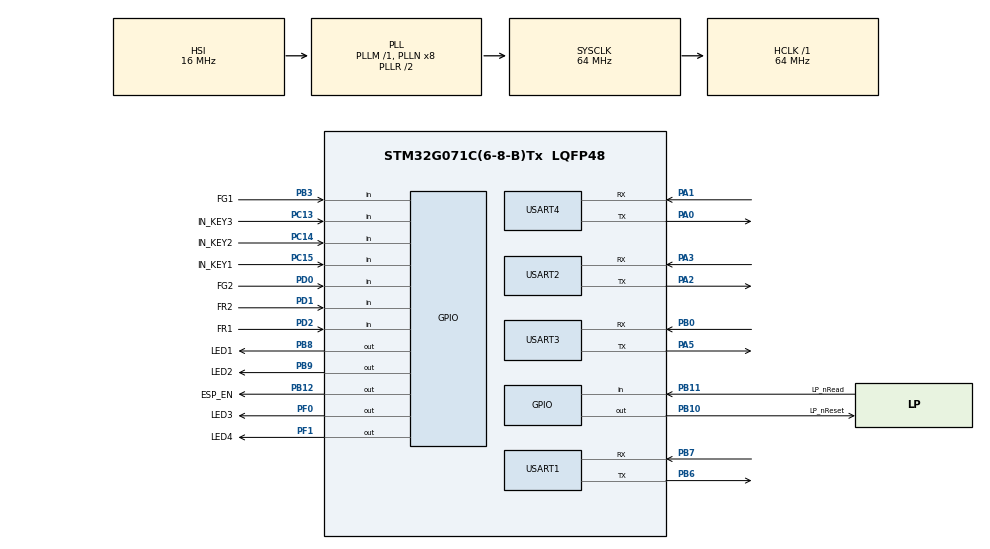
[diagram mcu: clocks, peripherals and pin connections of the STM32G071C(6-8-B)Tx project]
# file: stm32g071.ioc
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Dma.Request0=USART1_RX
Dma.Request1=USART1_TX
Dma.Request2=USART2_RX
Dma.Request3=USART2_TX
Dma.USART1_RX.0.Direction=DMA_PERIPH_TO_MEMORY
Dma.USART1_RX.0.EventEnable=DISABLE
Dma.USART1_RX.0.Instance=DMA1_Channel1
Dma.USART1_RX.0.MemDataAlignment=DMA_MDATAALIGN_BYTE
Dma.USART1_RX.0.MemInc=DMA_MINC_ENABLE
Dma.USART1_RX.0.Mode=DMA_NORMAL
Dma.USART1_RX.0.PeriphDataAlignment=DMA_PDATAALIGN_BYTE
Dma.USART1_RX.0.PeriphInc=DMA_PINC_DISABLE
Dma.USART1_RX.0.Polarity=HAL_DMAMUX_REQ_GEN_RISING
Dma.USART1_RX.0.Priority=DMA_PRIORITY_LOW
Dma.USART1_RX.0.RequestNumber=1
Dma.USART1_RX.0.SignalID=NONE
Dma.USART1_RX.0.SyncEnable=DISABLE
Dma.USART1_RX.0.SyncPolarity=HAL_DMAMUX_SYNC_NO_EVENT
Dma.USART1_RX.0.SyncRequestNumber=1
Dma.USART1_RX.0.SyncSignalID=NONE
Dma.USART1_TX.1.Direction=DMA_MEMORY_TO_PERIPH
Dma.USART1_TX.1.EventEnable=DISABLE
Dma.USART1_TX.1.Instance=DMA1_Channel2
Dma.USART1_TX.1.MemDataAlignment=DMA_MDATAALIGN_BYTE
Dma.USART1_TX.1.MemInc=DMA_MINC_ENABLE
Dma.USART1_TX.1.Mode=DMA_NORMAL
Dma.USART1_TX.1.PeriphDataAlignment=DMA_PDATAALIGN_BYTE
Dma.USART1_TX.1.PeriphInc=DMA_PINC_DISABLE
Dma.USART1_TX.1.Polarity=HAL_DMAMUX_REQ_GEN_RISING
Dma.USART1_TX.1.Priority=DMA_PRIORITY_LOW
Dma.USART1_TX.1.RequestNumber=1
Dma.USART1_TX.1.SignalID=NONE
Dma.USART1_TX.1.SyncEnable=DISABLE
Dma.USART1_TX.1.SyncPolarity=HAL_DMAMUX_SYNC_NO_EVENT
Dma.USART1_TX.1.SyncRequestNumber=1
Dma.USART1_TX.1.SyncSignalID=NONE
Dma.USART2_RX.2.Direction=DMA_PERIPH_TO_MEMORY
Dma.USART2_RX.2.EventEnable=DISABLE
Dma.USART2_RX.2.Instance=DMA1_Channel3
Dma.USART2_RX.2.MemDataAlignment=DMA_MDATAALIGN_BYTE
Dma.USART2_RX.2.MemInc=DMA_MINC_ENABLE
Dma.USART2_RX.2.Mode=DMA_NORMAL
Dma.USART2_RX.2.PeriphDataAlignment=DMA_PDATAALIGN_BYTE
Dma.USART2_RX.2.PeriphInc=DMA_PINC_DISABLE
Dma.USART2_RX.2.Polarity=HAL_DMAMUX_REQ_GEN_RISING
Dma.USART2_RX.2.Priority=DMA_PRIORITY_LOW
Dma.USART2_RX.2.RequestNumber=1
Dma.USART2_RX.2.SignalID=NONE
Dma.USART2_RX.2.SyncEnable=DISABLE
Dma.USART2_RX.2.SyncPolarity=HAL_DMAMUX_SYNC_NO_EVENT
Dma.USART2_RX.2.SyncRequestNumber=1
Dma.USART2_RX.2.SyncSignalID=NONE
Dma.USART2_TX.3.Direction=DMA_MEMORY_TO_PERIPH
Dma.USART2_TX.3.EventEnable=DISABLE
Dma.USART2_TX.3.Instance=DMA1_Channel4
Dma.USART2_TX.3.MemDataAlignment=DMA_MDATAALIGN_BYTE
Dma.USART2_TX.3.MemInc=DMA_MINC_ENABLE
Dma.USART2_TX.3.Mode=DMA_NORMAL
Dma.USART2_TX.3.PeriphDataAlignment=DMA_PDATAALIGN_BYTE
Dma.USART2_TX.3.PeriphInc=DMA_PINC_DISABLE
Dma.USART2_TX.3.Polarity=HAL_DMAMUX_REQ_GEN_RISING
Dma.USART2_TX.3.Priority=DMA_PRIORITY_LOW
Dma.USART2_TX.3.RequestNumber=1
Dma.USART2_TX.3.SignalID=NONE
Dma.USART2_TX.3.SyncEnable=DISABLE
Dma.USART2_TX.3.SyncPolarity=HAL_DMAMUX_SYNC_NO_EVENT
Dma.USART2_TX.3.SyncRequestNumber=1
Dma.USART2_TX.3.SyncSignalID=NONE
FREERTOS.BinarySemaphores01=uart1_send_sem,Dynamic,NULL;uart2_send_sem,Dynamic,NULL;uart3_send_sem,Dynamic,NULL;uart4_send_sem,Dynamic,NULL
FREERTOS.HEAP_NUMBER=3
FREERTOS.INCLUDE_eTaskGetState=1
FREERTOS.INCLUDE_pcTaskGetTaskName=1
FREERTOS.INCLUDE_uxTaskGetStackHighWaterMark=1
FREERTOS.INCLUDE_uxTaskGetStackHighWaterMark2=1
FREERTOS.INCLUDE_uxTaskPriorityGet=1
FREERTOS.INCLUDE_vTaskCleanUpResources=1
FREERTOS.INCLUDE_vTaskDelayUntil=1
FREERTOS.INCLUDE_vTaskDelete=1
FREERTOS.INCLUDE_vTaskPrioritySet=1
FREERTOS.INCLUDE_vTaskSuspend=1
FREERTOS.INCLUDE_xQueueGetMutexHolder=1
FREERTOS.INCLUDE_xSemaphoreGetMutexHolder=1
FREERTOS.INCLUDE_xTaskAbortDelay=1
FREERTOS.INCLUDE_xTaskGetCurrentTaskHandle=1
FREERTOS.INCLUDE_xTaskGetHandle=1
FREERTOS.INCLUDE_xTaskResumeFromISR=1
FREERTOS.Mutexes01=fsm_event_mtx,Dynamic,NULL;uart1_mtx,Dynamic,NULL;uart2_mtx,Dynamic,NULL;uart3_mtx,Dynamic,NULL;uart4_mtx,Dynamic,NULL
FREERTOS.Tasks01=default_thread,-3,128,default_thread_func,Default,NULL,Dynamic,NULL,NULL;main_thread,0,128,main_thread_func,As external,NULL,Dynamic,NULL,NULL;lp262_thread,0,128,lp262_thread_func,As external,NULL,Dynamic,NULL,NULL;uart_thread,3,128,uart_thread_func,As external,NULL,Dynamic,NULL,NULL
FREERTOS.configCHECK_FOR_STACK_OVERFLOW=2
FREERTOS.configENABLE_BACKWARD_COMPATIBILITY=1
FREERTOS.configGENERATE_RUN_TIME_STATS=1
FREERTOS.configMAX_TASK_NAME_LEN=16
FREERTOS.configRECORD_STACK_HIGH_ADDRESS=1
FREERTOS.configTOTAL_HEAP_SIZE=10240
FREERTOS.configUSE_APPLICATION_TASK_TAG=1
FREERTOS.configUSE_COUNTING_SEMAPHORES=1
FREERTOS.configUSE_NEWLIB_REENTRANT=1
FREERTOS.configUSE_RECURSIVE_MUTEXES=1
FREERTOS.configUSE_STATS_FORMATTING_FUNCTIONS=1
FREERTOS.configUSE_TASK_NOTIFICATIONS=1
FREERTOS.configUSE_TRACE_FACILITY=1
Mcu.Family=STM32G0
Mcu.Name=STM32G071C(6-8-B)Tx
Mcu.Package=LQFP48
NVIC.DMA1_Ch4_7_DMAMUX1_OVR_IRQn=true\:3\:0\:false\:false\:true\:true\:false\:true\:true
NVIC.DMA1_Channel1_IRQn=true\:3\:0\:false\:false\:true\:true\:false\:true\:true
NVIC.DMA1_Channel2_3_IRQn=true\:3\:0\:false\:false\:true\:true\:false\:true\:true
NVIC.TIM2_IRQn=true\:3\:0\:false\:false\:true\:false\:false\:true\:true
NVIC.TimeBase=TIM2_IRQn
NVIC.TimeBaseIP=TIM2
NVIC.USART1_IRQn=true\:3\:0\:false\:false\:true\:true\:true\:true\:true
NVIC.USART2_IRQn=true\:3\:0\:false\:false\:true\:true\:true\:true\:true
NVIC.USART3_4_LPUART1_IRQn=true\:3\:0\:false\:false\:true\:true\:true\:true\:true
PA0.Mode=Asynchronous
PA0.Signal=USART4_TX
PA1.Mode=Asynchronous
PA1.Signal=USART4_RX
PA13.Mode=Serial_Wire
PA13.Signal=SYS_SWDIO
PA14-BOOT0.Mode=Serial_Wire
PA14-BOOT0.Signal=SYS_SWCLK
PA2.Mode=Asynchronous
PA2.Signal=USART2_TX
PA3.Mode=Asynchronous
PA3.Signal=USART2_RX
PA5.Mode=Asynchronous
PA5.Signal=USART3_TX
PB0.Mode=Asynchronous
PB0.Signal=USART3_RX
PB10.GPIO_Label=LP_nReset
PB10.Signal=GPIO_Output
PB11.GPIO_Label=LP_nRead
PB11.Signal=GPIO_Input
PB12.GPIO_Label=ESP_EN
PB12.Signal=GPIO_Output
PB3.GPIO_Label=FG1
PB3.Signal=GPIO_Input
PB6.Mode=Asynchronous
PB6.Signal=USART1_TX
PB7.Mode=Asynchronous
PB7.Signal=USART1_RX
PB8.GPIO_Label=LED1
PB8.Signal=GPIO_Output
PB9.GPIO_Label=LED2
PB9.Signal=GPIO_Output
PC13.GPIO_Label=IN_KEY3
PC13.Signal=GPIO_Input
PC14-OSC32_IN\ (PC14).GPIO_Label=IN_KEY2
PC14-OSC32_IN\ (PC14).Signal=GPIO_Input
PC15-OSC32_OUT\ (PC15).GPIO_Label=IN_KEY1
PC15-OSC32_OUT\ (PC15).Signal=GPIO_Input
PC6.Signal=S_TIM3_CH1
PC7.Signal=S_TIM2_CH4
PD0.GPIO_Label=FG2
PD0.Signal=GPIO_Input
PD1.GPIO_Label=FR2
PD1.Signal=GPIO_Input
PD2.GPIO_Label=FR1
PD2.Signal=GPIO_Input
PF0-OSC_IN\ (PF0).GPIO_Label=LED3
PF0-OSC_IN\ (PF0).Signal=GPIO_Output
PF1-OSC_OUT\ (PF1).GPIO_Label=LED4
PF1-OSC_OUT\ (PF1).Signal=GPIO_Output
ProjectManager.HeapSize=0x3000
ProjectManager.StackSize=0x1000
ProjectManager.TargetToolchain=STM32CubeIDE
RCC.ADCFreq_Value=64000000
RCC.AHBFreq_Value=64000000
RCC.CortexFreq_Value=64000000
RCC.EXTERNAL_CLOCK_VALUE=48000
RCC.HCLKFreq_Value=64000000
RCC.HSE_VALUE=8000000
RCC.HSI_VALUE=16000000
RCC.LSE_VALUE=32768
RCC.PLLQ=RCC_PLLQ_DIV4
RCC.SYSCLKFreq_VALUE=64000000
RCC.SYSCLKSource=RCC_SYSCLKSOURCE_PLLCLK
RCC.VCOOutputFreq_Value=128000000
SH.S_TIM2_CH4.0=TIM2_CH4
SH.S_TIM3_CH1.0=TIM3_CH1
USART1.FIFOMode=FIFOMODE_ENABLE
USART1.VirtualMode-Asynchronous=VM_ASYNC
USART2.FIFOMode=FIFOMODE_DISABLE
USART2.VirtualMode-Asynchronous=VM_ASYNC
USART3.VirtualMode-Asynchronous=VM_ASYNC
USART4.VirtualMode-Asynchronous=VM_ASYNC
VP_CRC_VS_CRC.Mode=CRC_Activate
VP_FREERTOS_VS_CMSIS_V1.Mode=CMSIS_V1
VP_SYS_VS_DBSignals.Mode=DisableDeadBatterySignals
VP_SYS_VS_tim2.Mode=TIM2
VP_TIM1_VS_ClockSourceINT.Mode=Internal
board=custom

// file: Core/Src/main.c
/* USER CODE BEGIN Header */
/**
  ******************************************************************************
  * @file           : main.c
  * @brief          : Main program body
  ******************************************************************************
  * @attention
  *
  * Copyright (c) 2024 STMicroelectronics.
  * All rights reserved.
  *
  * This software is licensed under terms that can be found in the LICENSE file
  * in the root directory of this software component.
  * If no LICENSE file comes with this software, it is provided AS-IS.
  *
  ******************************************************************************
  */
/* USER CODE END Header */
#include "main.h"
#include "cmsis_os.h"
#include "crc.h"
#include "dma.h"
#include "tim.h"
#include "usart.h"
#include "gpio.h"

void SystemClock_Config(void);
void MX_FREERTOS_Init(void);

int main(void)
{

  /* MCU Configuration--------------------------------------------------------*/

  /* Reset of all peripherals, Initializes the Flash interface and the Systick. */
  HAL_Init();

  /* Configure the system clock */
  SystemClock_Config();

  /* Initialize all configured peripherals */
  MX_GPIO_Init();
  MX_DMA_Init();
  MX_CRC_Init();
  MX_TIM1_Init();
  MX_USART1_UART_Init();
  MX_USART2_UART_Init();
  MX_USART3_UART_Init();
  MX_USART4_UART_Init();

  /* Call init function for freertos objects (in cmsis_os2.c) */
  MX_FREERTOS_Init();

  /* Start scheduler */
  osKernelStart();

  /* We should never get here as control is now taken by the scheduler */

  /* Infinite loop */
  while (1)
  {

  }
}

void SystemClock_Config(void)
{
  RCC_OscInitTypeDef RCC_OscInitStruct = {0};
  RCC_ClkInitTypeDef RCC_ClkInitStruct = {0};

  /** Configure the main internal regulator output voltage
  */
  HAL_PWREx_ControlVoltageScaling(PWR_REGULATOR_VOLTAGE_SCALE1);

  /** Initializes the RCC Oscillators according to the specified parameters
  * in the RCC_OscInitTypeDef structure.
  */
  RCC_OscInitStruct.OscillatorType = RCC_OSCILLATORTYPE_HSI;
  RCC_OscInitStruct.HSIState = RCC_HSI_ON;
  RCC_OscInitStruct.HSIDiv = RCC_HSI_DIV1;
  RCC_OscInitStruct.HSICalibrationValue = RCC_HSICALIBRATION_DEFAULT;
  RCC_OscInitStruct.PLL.PLLState = RCC_PLL_ON;
  RCC_OscInitStruct.PLL.PLLSource = RCC_PLLSOURCE_HSI;
  RCC_OscInitStruct.PLL.PLLM = RCC_PLLM_DIV1;
  RCC_OscInitStruct.PLL.PLLN = 8;
  RCC_OscInitStruct.PLL.PLLP = RCC_PLLP_DIV2;
  RCC_OscInitStruct.PLL.PLLQ = RCC_PLLQ_DIV4;
  RCC_OscInitStruct.PLL.PLLR = RCC_PLLR_DIV2;
  if (HAL_RCC_OscConfig(&RCC_OscInitStruct) != HAL_OK)
  {
    Error_Handler();
  }

  /** Initializes the CPU, AHB and APB buses clocks
  */
  RCC_ClkInitStruct.ClockType = RCC_CLOCKTYPE_HCLK|RCC_CLOCKTYPE_SYSCLK
                              |RCC_CLOCKTYPE_PCLK1;
  RCC_ClkInitStruct.SYSCLKSource = RCC_SYSCLKSOURCE_PLLCLK;
  RCC_ClkInitStruct.AHBCLKDivider = RCC_SYSCLK_DIV1;
  RCC_ClkInitStruct.APB1CLKDivider = RCC_HCLK_DIV1;

  if (HAL_RCC_ClockConfig(&RCC_ClkInitStruct, FLASH_LATENCY_2) != HAL_OK)
  {
    Error_Handler();
  }
}

void HAL_TIM_PeriodElapsedCallback(TIM_HandleTypeDef *htim)
{
  if (htim->Instance == TIM2) {
    HAL_IncTick();
  }
}

void Error_Handler(void)
{
  __disable_irq();
  while (1)
  {
  }
}

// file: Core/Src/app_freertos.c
/* USER CODE BEGIN Header */
/**
  ******************************************************************************
  * File Name          : app_freertos.c
  * Description        : Code for freertos applications
  ******************************************************************************
  * @attention
  *
  * Copyright (c) 2024 STMicroelectronics.
  * All rights reserved.
  *
  * This software is licensed under terms that can be found in the LICENSE file
  * in the root directory of this software component.
  * If no LICENSE file comes with this software, it is provided AS-IS.
  *
  ******************************************************************************
  */
/* USER CODE END Header */

#include "FreeRTOS.h"
#include "task.h"
#include "main.h"
#include "cmsis_os.h"

osThreadId default_threadHandle;
osThreadId main_threadHandle;
osThreadId lp262_threadHandle;
osThreadId uart_threadHandle;
osMutexId fsm_event_mtxHandle;
osMutexId uart1_mtxHandle;
osMutexId uart2_mtxHandle;
osMutexId uart3_mtxHandle;
osMutexId uart4_mtxHandle;
osSemaphoreId uart1_send_semHandle;
osSemaphoreId uart2_send_semHandle;
osSemaphoreId uart3_send_semHandle;
osSemaphoreId uart4_send_semHandle;

/* USER CODE BEGIN FunctionPrototypes */
extern void lp262_thread_init(void);
extern void uart_thread_init(void);
extern void main_thread_init(void);
extern void debug_init(void);
/* USER CODE END FunctionPrototypes */

void default_thread_func(void const * argument);
extern void main_thread_func(void const * argument);
extern void lp262_thread_func(void const * argument);
extern void uart_thread_func(void const * argument);

void MX_FREERTOS_Init(void); /* (MISRA C 2004 rule 8.1) */

/* Hook prototypes */
void configureTimerForRunTimeStats(void);
unsigned long getRunTimeCounterValue(void);
void vApplicationStackOverflowHook(xTaskHandle xTask, signed char *pcTaskName);

/* USER CODE BEGIN 1 */
/* Functions needed when configGENERATE_RUN_TIME_STATS is on */
__weak void configureTimerForRunTimeStats(void)
{

}

__weak unsigned long getRunTimeCounterValue(void)
{
return 0;
}
/* USER CODE END 1 */

/* USER CODE BEGIN 4 */
__weak void vApplicationStackOverflowHook(TaskHandle_t xTask, signed char *pcTaskName)
{
   /* Run time stack overflow checking is performed if
   configCHECK_FOR_STACK_OVERFLOW is defined to 1 or 2. This hook function is
   called if a stack overflow is detected. */
}
/* USER CODE END 4 */

void MX_FREERTOS_Init(void) {
  /* USER CODE BEGIN Init */
  lp262_thread_init();
  uart_thread_init();
  main_thread_init();
  // keep debug init at the last
  debug_init();
  /* USER CODE END Init */
  /* Create the mutex(es) */
  /* definition and creation of fsm_event_mtx */
  osMutexDef(fsm_event_mtx);
  fsm_event_mtxHandle = osMutexCreate(osMutex(fsm_event_mtx));

  /* definition and creation of uart1_mtx */
  osMutexDef(uart1_mtx);
  uart1_mtxHandle = osMutexCreate(osMutex(uart1_mtx));

  /* definition and creation of uart2_mtx */
  osMutexDef(uart2_mtx);
  uart2_mtxHandle = osMutexCreate(osMutex(uart2_mtx));

  /* definition and creation of uart3_mtx */
  osMutexDef(uart3_mtx);
  uart3_mtxHandle = osMutexCreate(osMutex(uart3_mtx));

  /* definition and creation of uart4_mtx */
  osMutexDef(uart4_mtx);
  uart4_mtxHandle = osMutexCreate(osMutex(uart4_mtx));

  /* Create the semaphores(s) */
  /* definition and creation of uart1_send_sem */
  osSemaphoreDef(uart1_send_sem);
  uart1_send_semHandle = osSemaphoreCreate(osSemaphore(uart1_send_sem), 1);

  /* definition and creation of uart2_send_sem */
  osSemaphoreDef(uart2_send_sem);
  uart2_send_semHandle = osSemaphoreCreate(osSemaphore(uart2_send_sem), 1);

  /* definition and creation of uart3_send_sem */
  osSemaphoreDef(uart3_send_sem);
  uart3_send_semHandle = osSemaphoreCreate(osSemaphore(uart3_send_sem), 1);

  /* definition and creation of uart4_send_sem */
  osSemaphoreDef(uart4_send_sem);
  uart4_send_semHandle = osSemaphoreCreate(osSemaphore(uart4_send_sem), 1);

  /* Create the thread(s) */
  /* definition and creation of default_thread */
  osThreadDef(default_thread, default_thread_func, osPriorityIdle, 0, 128);
  default_threadHandle = osThreadCreate(osThread(default_thread), NULL);

  /* definition and creation of main_thread */
  osThreadDef(main_thread, main_thread_func, osPriorityNormal, 0, 128);
  main_threadHandle = osThreadCreate(osThread(main_thread), NULL);

  /* definition and creation of lp262_thread */
  osThreadDef(lp262_thread, lp262_thread_func, osPriorityNormal, 0, 128);
  lp262_threadHandle = osThreadCreate(osThread(lp262_thread), NULL);

  /* definition and creation of uart_thread */
  osThreadDef(uart_thread, uart_thread_func, osPriorityRealtime, 0, 128);
  uart_threadHandle = osThreadCreate(osThread(uart_thread), NULL);

}

void default_thread_func(void const * argument)
{
  /* USER CODE BEGIN default_thread_func */
  /* Infinite loop */
  for(;;)
  {
	HAL_GPIO_TogglePin(LED4_GPIO_Port, LED4_Pin);
    osDelay(500);
  }
  /* USER CODE END default_thread_func */
}
